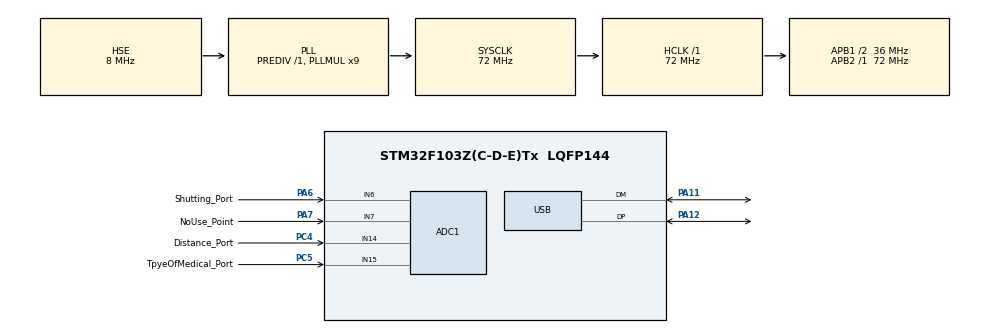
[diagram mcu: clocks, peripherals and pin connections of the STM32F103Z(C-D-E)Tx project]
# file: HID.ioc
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ADC1.Channel-0\#ChannelRegularConversion=ADC_CHANNEL_14
ADC1.Channel-1\#ChannelRegularConversion=ADC_CHANNEL_15
ADC1.Channel-2\#ChannelRegularConversion=ADC_CHANNEL_6
ADC1.Channel-3\#ChannelRegularConversion=ADC_CHANNEL_7
ADC1.ContinuousConvMode=ENABLE
ADC1.DataAlign=ADC_DATAALIGN_RIGHT
ADC1.DiscontinuousConvMode=DISABLE
ADC1.EnableAnalogWatchDog=false
ADC1.EnableRegularConversion=ENABLE
ADC1.ExternalTrigConv=ADC_SOFTWARE_START
ADC1.InjNumberOfConversion=0
ADC1.NbrOfConversion=4
ADC1.NbrOfConversionFlag=1
ADC1.Rank-0\#ChannelRegularConversion=1
ADC1.Rank-1\#ChannelRegularConversion=2
ADC1.Rank-2\#ChannelRegularConversion=3
ADC1.Rank-3\#ChannelRegularConversion=4
ADC1.SamplingTime-0\#ChannelRegularConversion=ADC_SAMPLETIME_239CYCLES_5
ADC1.SamplingTime-1\#ChannelRegularConversion=ADC_SAMPLETIME_239CYCLES_5
ADC1.SamplingTime-2\#ChannelRegularConversion=ADC_SAMPLETIME_239CYCLES_5
ADC1.SamplingTime-3\#ChannelRegularConversion=ADC_SAMPLETIME_239CYCLES_5
ADC1.ScanConvMode=ADC_SCAN_ENABLE
ADC1.master=1
Dma.ADC1.0.Direction=DMA_PERIPH_TO_MEMORY
Dma.ADC1.0.Instance=DMA1_Channel1
Dma.ADC1.0.MemDataAlignment=DMA_MDATAALIGN_HALFWORD
Dma.ADC1.0.MemInc=DMA_MINC_ENABLE
Dma.ADC1.0.Mode=DMA_CIRCULAR
Dma.ADC1.0.PeriphDataAlignment=DMA_PDATAALIGN_HALFWORD
Dma.ADC1.0.PeriphInc=DMA_PINC_DISABLE
Dma.ADC1.0.Priority=DMA_PRIORITY_HIGH
Dma.Request0=ADC1
Mcu.Family=STM32F1
Mcu.Name=STM32F103Z(C-D-E)Tx
Mcu.Package=LQFP144
NVIC.DMA1_Channel1_IRQn=true\:0\:0\:false\:false\:true\:false
NVIC.PriorityGroup=NVIC_PRIORITYGROUP_4
NVIC.TIM1_UP_IRQn=true\:0\:0\:false\:false\:true\:false
NVIC.TIM6_IRQn=true\:0\:0\:false\:false\:true\:true
NVIC.TimeBase=TIM1_UP_IRQn
NVIC.TimeBaseIP=TIM1
NVIC.USB_HP_CAN1_TX_IRQn=true\:0\:0\:false\:false\:true\:true
NVIC.USB_LP_CAN1_RX0_IRQn=true\:0\:0\:false\:false\:true\:false
OSC_IN.Mode=HSE-External-Oscillator
OSC_IN.Signal=RCC_OSC_IN
OSC_OUT.Mode=HSE-External-Oscillator
OSC_OUT.Signal=RCC_OSC_OUT
PA11.Mode=Device
PA11.Signal=USB_DM
PA12.Mode=Device
PA12.Signal=USB_DP
PA13.Mode=Trace_Asynchronous_SW
PA13.Signal=SYS_JTMS-SWDIO
PA14.Mode=Trace_Asynchronous_SW
PA14.Signal=SYS_JTCK-SWCLK
PA6.GPIO_Label=Shutting_Port
PA6.Signal=ADCx_IN6
PA7.GPIO_Label=NoUse_Point
PA7.Signal=ADCx_IN7
PB3.Mode=Trace_Asynchronous_SW
PB3.Signal=SYS_JTDO-TRACESWO
PC4.GPIO_Label=Distance_Port
PC4.Signal=ADCx_IN14
PC5.GPIO_Label=TpyeOfMedical_Port
PC5.Signal=ADCx_IN15
ProjectManager.HeapSize=0x500
ProjectManager.StackSize=0x2000
ProjectManager.TargetToolchain=MDK-ARM V5
RCC.ADCPresc=RCC_ADCPCLK2_DIV6
RCC.AHBFreq_Value=72000000
RCC.APB1CLKDivider=RCC_HCLK_DIV2
RCC.APB1Freq_Value=36000000
RCC.APB1TimFreq_Value=72000000
RCC.APB2Freq_Value=72000000
RCC.APB2TimFreq_Value=72000000
RCC.HCLKFreq_Value=72000000
RCC.PLLMUL=RCC_PLL_MUL9
RCC.SYSCLKFreq_VALUE=72000000
RCC.SYSCLKSource=RCC_SYSCLKSOURCE_PLLCLK
RCC.USBFreq_Value=48000000
RCC.USBPrescaler=RCC_USBCLKSOURCE_PLL_DIV1_5
SH.ADCx_IN14.0=ADC1_IN14,IN14
SH.ADCx_IN15.0=ADC1_IN15,IN15
SH.ADCx_IN6.0=ADC1_IN6,IN6
SH.ADCx_IN7.0=ADC1_IN7,IN7
TIM6.Period=999
TIM6.Prescaler=71
USB.ep0_mps=DEP0CTL_MPS_64
USB_DEVICE.CLASS_NAME_FS=CUSTOMHID
USB_DEVICE.MANUFACTURER_STRING=CHUXINMEDICAL
USB_DEVICE.PID_CUSTOMHID_FS=0x211B
USB_DEVICE.VID=0x411A
USB_DEVICE.VirtualMode=CustomHid
USB_DEVICE.VirtualModeFS=Custom_Hid_FS
VP_SYS_VS_tim1.Mode=TIM1
VP_TIM6_VS_ClockSourceINT.Mode=Enable_Timer
VP_USB_DEVICE_VS_USB_DEVICE_CUSTOM_HID_FS.Mode=CUSTOM_HID_FS
board=chuanci

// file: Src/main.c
/*
  ���������ӡ��Ա����ṩHID ��ֲ���룬�Թ�������
	 ��ӭ��ͬ̽��Ƕ��ʽ��
	 https://shop198134226.taobao.com/shop/view_shop.htm?spm=a313o.201708ban.0.d53.64f0197aOrWx00&mytmenu=mdianpu&user_number_id=106855850
*/

#include "main.h"
#include "stm32f1xx_hal.h"
#include "adc.h"
#include "dma.h"
#include "tim.h"
#include "usb_device.h"
#include "gpio.h"

/* USER CODE BEGIN Includes */
#include "usbd_pack.h"
/* USER CODE END Includes */

/* USER CODE BEGIN PV */
/* Private variables ---------------------------------------------------------*/

/* USER CODE END PV */

void SystemClock_Config(void);

/* USER CODE BEGIN PFP */
/* Private function prototypes -----------------------------------------------*/

/* USER CODE END PFP */

/* USER CODE BEGIN 0 */
extern __IO uint16_t ADCConvertedValue[6];
/* USER CODE END 0 */

int main(void)
{

  /* MCU Configuration----------------------------------------------------------*/

  /* Reset of all peripherals, Initializes the Flash interface and the Systick. */
  HAL_Init();

  /* Configure the system clock */
  SystemClock_Config();

  /* Initialize all configured peripherals */
  MX_GPIO_Init();
  MX_DMA_Init();
  MX_USB_DEVICE_Init();
  MX_ADC1_Init();
  MX_TIM6_Init();
  /* USER CODE BEGIN 2 */
  HAL_ADC_Start_DMA(&hadc1, (uint32_t *)ADCConvertedValue,4);
  /* USER CODE END 2 */

  /* Infinite loop */
  while (1)
  {
  USB_Mission();
  }

}

void SystemClock_Config(void)
{

  RCC_OscInitTypeDef RCC_OscInitStruct;
  RCC_ClkInitTypeDef RCC_ClkInitStruct;
  RCC_PeriphCLKInitTypeDef PeriphClkInit;

    /**Initializes the CPU, AHB and APB busses clocks
    */
  RCC_OscInitStruct.OscillatorType = RCC_OSCILLATORTYPE_HSE;
  RCC_OscInitStruct.HSEState = RCC_HSE_ON;
  RCC_OscInitStruct.HSEPredivValue = RCC_HSE_PREDIV_DIV1;
  RCC_OscInitStruct.HSIState = RCC_HSI_ON;
  RCC_OscInitStruct.PLL.PLLState = RCC_PLL_ON;
  RCC_OscInitStruct.PLL.PLLSource = RCC_PLLSOURCE_HSE;
  RCC_OscInitStruct.PLL.PLLMUL = RCC_PLL_MUL9;
  if (HAL_RCC_OscConfig(&RCC_OscInitStruct) != HAL_OK)
  {
    _Error_Handler(__FILE__, __LINE__);
  }

    /**Initializes the CPU, AHB and APB busses clocks
    */
  RCC_ClkInitStruct.ClockType = RCC_CLOCKTYPE_HCLK|RCC_CLOCKTYPE_SYSCLK
                              |RCC_CLOCKTYPE_PCLK1|RCC_CLOCKTYPE_PCLK2;
  RCC_ClkInitStruct.SYSCLKSource = RCC_SYSCLKSOURCE_PLLCLK;
  RCC_ClkInitStruct.AHBCLKDivider = RCC_SYSCLK_DIV1;
  RCC_ClkInitStruct.APB1CLKDivider = RCC_HCLK_DIV2;
  RCC_ClkInitStruct.APB2CLKDivider = RCC_HCLK_DIV1;

  if (HAL_RCC_ClockConfig(&RCC_ClkInitStruct, FLASH_LATENCY_2) != HAL_OK)
  {
    _Error_Handler(__FILE__, __LINE__);
  }

  PeriphClkInit.PeriphClockSelection = RCC_PERIPHCLK_ADC|RCC_PERIPHCLK_USB;
  PeriphClkInit.AdcClockSelection = RCC_ADCPCLK2_DIV6;
  PeriphClkInit.UsbClockSelection = RCC_USBCLKSOURCE_PLL_DIV1_5;
  if (HAL_RCCEx_PeriphCLKConfig(&PeriphClkInit) != HAL_OK)
  {
    _Error_Handler(__FILE__, __LINE__);
  }

    /**Configure the Systick interrupt time
    */
  HAL_SYSTICK_Config(HAL_RCC_GetHCLKFreq()/1000);

    /**Configure the Systick
    */
  HAL_SYSTICK_CLKSourceConfig(SYSTICK_CLKSOURCE_HCLK);

  /* SysTick_IRQn interrupt configuration */
  HAL_NVIC_SetPriority(SysTick_IRQn, 0, 0);
}

void HAL_TIM_PeriodElapsedCallback(TIM_HandleTypeDef *htim)
{
  if (htim->Instance == TIM1) {
    HAL_IncTick();
  }
}

void _Error_Handler(char *file, int line)
{
  while(1)
  {
  }
}

/************************ (C) COPYRIGHT STMicroelectronics *****END OF FILE****/
